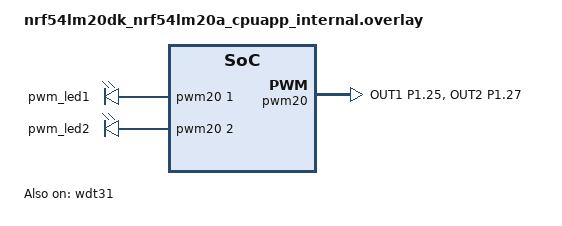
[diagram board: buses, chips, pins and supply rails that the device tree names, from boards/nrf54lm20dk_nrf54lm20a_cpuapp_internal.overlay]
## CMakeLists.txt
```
#
# Copyright (c) 2022 Nordic Semiconductor ASA
#
# SPDX-License-Identifier: LicenseRef-Nordic-5-Clause
#

cmake_minimum_required(VERSION 3.20.0)

find_package(Zephyr HINTS $ENV{ZEPHYR_BASE})

project(matter-window-app)

# Enable GNU STD support.
include(${ZEPHYR_CONNECTEDHOMEIP_MODULE_DIR}/config/nrfconnect/app/enable-gnu-std.cmake)

# NORDIC SDK APP START

# Include all source files that are located in the Matter common directory.
include(${ZEPHYR_NRF_MODULE_DIR}/samples/matter/common/cmake/source_common.cmake)

# Include Data Model utils
include(${ZEPHYR_NRF_MODULE_DIR}/samples/matter/common/cmake/data_model.cmake)

target_include_directories(app PRIVATE
    src
    ${CONFIG_NCS_MATTER_ZAP_FILES_PATH}
)

target_sources(app PRIVATE
    src/app_task.cpp
    src/window_covering.cpp
    src/main.cpp
    src/zcl_callbacks.cpp
)

ncs_configure_data_model(
    ZAP_FILE ${CMAKE_CURRENT_SOURCE_DIR}/${CONFIG_NCS_MATTER_ZAP_FILES_PATH}/window-app.zap
)
# NORDIC SDK APP END
```

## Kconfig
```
#
# Copyright (c) 2022 Nordic Semiconductor ASA
#
# SPDX-License-Identifier: LicenseRef-Nordic-5-Clause
#

mainmenu "Matter nRF Connect Window Covering Example Application"

config STATE_LEDS
	bool "Use LEDs to indicate the device state"
	default y
	help
	  Use LEDs to render the current state of the device such as the progress of commissioning of
	  the device into a network or the factory reset initiation. Note that setting this option to
	  'n' does not disable the LED indicating the state of the simulated bolt.

if MPSL_FEM

config OPENTHREAD_DEFAULT_TX_POWER
	int "Set the default 802.15.4 output power (dBm) for device with FEM"
	range -40 20
	default 20
	help
	  Use this setting to set the default Thread (802.15.4) output power for device that
	  uses FEM. This value has a unit in dBm and represents the Tx power at Antenna port of FEM device.

# override FEM GAIN to 20 dB as a default
# see subsys/mpsl/fem/Kconfig
# Leave MPSL_FEM_NRF21540_TX_GAIN_DB unchanged when OPENTHREAD_DEFAULT_TX_POWER=0 
# to set the output power to a similar value as for nRF52840DK.
config MPSL_FEM_NRF21540_TX_GAIN_DB
	default 20 if OPENTHREAD_DEFAULT_TX_POWER != 0

endif # MPSL_FEM


source "${ZEPHYR_BASE}/../modules/lib/matter/config/nrfconnect/chip-module/Kconfig.features"
source "${ZEPHYR_BASE}/../modules/lib/matter/config/nrfconnect/chip-module/Kconfig.defaults"
source "Kconfig.zephyr"
```

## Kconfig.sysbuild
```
#
# Copyright (c) 2023 Nordic Semiconductor ASA
#
# SPDX-License-Identifier: LicenseRef-Nordic-5-Clause
#

config PARTITION_MANAGER
	default n if SOC_SERIES_NRF52X || SOC_NRF54L15 || SOC_NRF54LM20A

#### Radio core selection
config NRF_DEFAULT_IPC_RADIO
	default y

# Enable IEEE802.15.4 serialization to network core
# This config automatically pulls in the `overlay-802154.conf` in the ipc_radio image
config NETCORE_IPC_RADIO_IEEE802154
	default y if SOC_SERIES_NRF53X

# Enable Bluetooth serialization to network core
# This config automatically pulls in the `overlay-bt_hci_ipc.conf` in the ipc_radio image
config NETCORE_IPC_RADIO_BT_HCI_IPC
	default y if SOC_SERIES_NRF53X

#### Bootloader
choice BOOTLOADER
	default BOOTLOADER_MCUBOOT if !BOARD_NRF21540DK
endchoice

if BOOTLOADER_MCUBOOT

#### DFU multi-image support
config DFU_MULTI_IMAGE_PACKAGE_BUILD
	default y

config DFU_MULTI_IMAGE_PACKAGE_APP
	default y

config PM_EXTERNAL_FLASH_MCUBOOT_SECONDARY
	default y

#### DFU network core configuration
if SOC_SERIES_NRF53X

choice MCUBOOT_MODE
	default MCUBOOT_MODE_OVERWRITE_ONLY
endchoice

choice BOOT_SIGNATURE_TYPE
	default BOOT_SIGNATURE_TYPE_RSA
endchoice

config SECURE_BOOT_NETCORE
	default y

config NETCORE_APP_UPDATE
	default y

config DFU_MULTI_IMAGE_PACKAGE_NET
	default y

endif # SOC_SERIES_NRF53X

if BOARD_NRF54L15DK || BOARD_NRF54LM20DK

# Disable checking the external drivers for nRF54L15 and nRF54LM20 DKs.
config PM_OVERRIDE_EXTERNAL_DRIVER_CHECK
	default y

endif # BOARD_NRF54L15DK || BOARD_NRF54LM20DK

endif # BOOTLOADER_MCUBOOT

#### Enable generating factory data
config MATTER_FACTORY_DATA_GENERATE
	default y if !BOARD_NRF21540DK

source "share/sysbuild/Kconfig"
```

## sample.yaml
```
sample:
  description: Matter Window Covering example
  name: Matter Window Covering
tests:
  sample.matter.window_cover.debug:
    sysbuild: true
    build_only: true
    integration_platforms:
      - nrf52840dk/nrf52840
      - nrf5340dk/nrf5340/cpuapp
    platform_allow: nrf52840dk/nrf52840 nrf5340dk/nrf5340/cpuapp
    tags: sysbuild
  sample.matter.window_cover.release:
    sysbuild: true
    build_only: true
    extra_args: FILE_SUFFIX=release
      SB_CONFIG_BOOTLOADER_MCUBOOT=y SB_CONFIG_PARTITION_MANAGER=y
    integration_platforms:
      - nrf52840dk/nrf52840
      - nrf5340dk/nrf5340/cpuapp
      - nrf54l15pdk/nrf54l15/cpuapp
      - nrf54l15pdk@0.3.0/nrf54l15/cpuapp
    platform_allow: nrf52840dk/nrf52840 nrf5340dk/nrf5340/cpuapp
      nrf54l15pdk/nrf54l15/cpuapp nrf54l15pdk@0.3.0/nrf54l15/cpuapp
    tags: sysbuild
```

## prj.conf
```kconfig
#
# Copyright (c) 2022 Nordic Semiconductor ASA
#
# SPDX-License-Identifier: LicenseRef-Nordic-5-Clause
#

# This sample uses Kconfig.defaults to set options common for all
# samples. This file should contain only options specific for this sample
# or overrides of default values.

# Enable CHIP
CONFIG_CHIP=y
CONFIG_CHIP_PROJECT_CONFIG="src/chip_project_config.h"
# 32784 == 0x8010 (example window-app)
CONFIG_CHIP_DEVICE_PRODUCT_ID=32784
CONFIG_STD_CPP17=y

# Enable Matter pairing automatically on application start.
CONFIG_CHIP_ENABLE_PAIRING_AUTOSTART=y

# Enable Matter extended announcement and increase duration to 1 hour.
CONFIG_CHIP_BLE_EXT_ADVERTISING=y
CONFIG_CHIP_BLE_ADVERTISING_DURATION=60

# Add support for LEDs and buttons on Nordic development kits
CONFIG_DK_LIBRARY=y

# PWM support
CONFIG_PWM=y

# OpenThread configs
CONFIG_OPENTHREAD_NORDIC_LIBRARY_MTD=y
CONFIG_OPENTHREAD_MTD=y
CONFIG_OPENTHREAD_FTD=n
CONFIG_CHIP_ENABLE_ICD_SUPPORT=y
CONFIG_CHIP_THREAD_SSED=y
CONFIG_CHIP_ICD_SLOW_POLL_INTERVAL=500
CONFIG_CHIP_ICD_FAST_POLLING_INTERVAL=500

# Bluetooth Low Energy configuration
CONFIG_BT_DEVICE_NAME="MatterWinCov"

# Suspend devices when the CPU goes into sleep
CONFIG_PM_DEVICE=y

# Stack size settings
CONFIG_IEEE802154_NRF5_RX_STACK_SIZE=1024

# Other settings
CONFIG_THREAD_NAME=y
CONFIG_MPU_STACK_GUARD=y
CONFIG_RESET_ON_FATAL_ERROR=n
CONFIG_CHIP_LIB_SHELL=y
CONFIG_NCS_MATTER_TEST_SHELL=y

# Reduce application size
CONFIG_USE_SEGGER_RTT=n

# Enable Factory Data feature
CONFIG_CHIP_FACTORY_DATA=y
CONFIG_CHIP_FACTORY_DATA_BUILD=y
```

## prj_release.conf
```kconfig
#
# Copyright (c) 2022 Nordic Semiconductor ASA
#
# SPDX-License-Identifier: LicenseRef-Nordic-5-Clause
#

# This sample uses Kconfig.defaults to set options common for all
# samples. This file should contain only options specific for this sample
# or overrides of default values.

# Enable CHIP
CONFIG_CHIP=y
CONFIG_CHIP_PROJECT_CONFIG="src/chip_project_config.h"
# 32784 == 0x8010 (example window-app)
CONFIG_CHIP_DEVICE_PRODUCT_ID=32784
CONFIG_STD_CPP17=y

# Enable Matter pairing automatically on application start.
CONFIG_CHIP_ENABLE_PAIRING_AUTOSTART=y

# Enable Matter extended announcement and increase duration to 1 hour.
CONFIG_CHIP_BLE_EXT_ADVERTISING=y
CONFIG_CHIP_BLE_ADVERTISING_DURATION=60

# Add support for LEDs and buttons on Nordic development kits
CONFIG_DK_LIBRARY=y

# Try to disable unused RAM blocks to reduce power consumption
CONFIG_RAM_POWER_DOWN_LIBRARY=y

# PWM support
CONFIG_PWM=y

# OpenThread configs
CONFIG_OPENTHREAD_NORDIC_LIBRARY_MTD=y
CONFIG_OPENTHREAD_MTD=y
CONFIG_OPENTHREAD_FTD=n
CONFIG_CHIP_ENABLE_ICD_SUPPORT=y
CONFIG_CHIP_THREAD_SSED=y
CONFIG_CHIP_ICD_SLOW_POLL_INTERVAL=500
CONFIG_CHIP_ICD_FAST_POLLING_INTERVAL=500

# Bluetooth Low Energy configuration
CONFIG_BT_DEVICE_NAME="MatterWinCov"

# Suspend devices when the CPU goes into sleep
CONFIG_PM_DEVICE=y

# Stack size settings
CONFIG_IEEE802154_NRF5_RX_STACK_SIZE=1024

# Enable system reset on fatal error
CONFIG_RESET_ON_FATAL_ERROR=y

# Disable all debug features
CONFIG_USE_SEGGER_RTT=n
CONFIG_SHELL=n
CONFIG_OPENTHREAD_SHELL=n
CONFIG_CONSOLE=n
CONFIG_UART_CONSOLE=n
CONFIG_SERIAL=n
CONFIG_LOG=n
CONFIG_LOG_MODE_MINIMAL=n
CONFIG_ASSERT_VERBOSE=n
CONFIG_ASSERT_NO_FILE_INFO=y
CONFIG_PRINTK=n
CONFIG_PRINTK_SYNC=n
CONFIG_THREAD_NAME=n
CONFIG_BOOT_BANNER=n

# Enable Factory Data feature
CONFIG_CHIP_FACTORY_DATA=y
CONFIG_CHIP_FACTORY_DATA_BUILD=y

# Enable Watchdog
CONFIG_NCS_MATTER_WATCHDOG=y

# Enable LTO to decrease the flash usage.
CONFIG_LTO=y
CONFIG_ISR_TABLES_LOCAL_DECLARATION=y
```

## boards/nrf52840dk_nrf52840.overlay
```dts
/*
 * Copyright (c) 2021 Nordic Semiconductor ASA
 *
 * SPDX-License-Identifier: LicenseRef-Nordic-5-Clause
 */

#include "../../common/boards/nrf52840dk_nrf52840_partitions.dtsi"

/ {
	/*
	* Configure LED2 and LED3 to show the state of the
	* window cover,by using the LED's brightness level.
	*/
	aliases {
		pwm-led1 = &pwm_led1;
		pwm-led2 = &pwm_led2;
	};

	pwmleds {
		pwm_led1: pwm_led_1 {
			pwms = <&pwm0 1 PWM_MSEC(20) PWM_POLARITY_INVERTED>;
		};
		pwm_led2: pwm_led_2 {
			pwms = <&pwm0 2 PWM_MSEC(20) PWM_POLARITY_INVERTED>;
		};
	};
};

&pwm0 {
	pinctrl-0 = <&pwm0_default_alt>;
	pinctrl-1 = <&pwm0_sleep_alt>;
	pinctrl-names = "default", "sleep";
};

&pinctrl {
	pwm0_default_alt: pwm0_default_alt {
		group1 {
			psels = <NRF_PSEL(PWM_OUT1, 0, 14)>, <NRF_PSEL(PWM_OUT2, 0, 15)>;
			nordic,invert;
		};
	};

	pwm0_sleep_alt: pwm0_sleep_alt {
		group1 {
			psels = <NRF_PSEL(PWM_OUT1, 0, 14)>, <NRF_PSEL(PWM_OUT2, 0, 15)>;
			low-power-enable;
		};
	};
};

/* Disable unused peripherals to reduce power consumption */
&adc {
	status = "disabled";
};

&uart1 {
	status = "disabled";
};

&i2c0 {
	status = "disabled";
};

&spi1 {
	status = "disabled";
};

&spi3 {
	status = "disabled";
};

&usbd {
	status = "disabled";
};
```

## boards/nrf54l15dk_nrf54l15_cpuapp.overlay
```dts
/*
 * Copyright (c) 2024 Nordic Semiconductor ASA
 *
 * SPDX-License-Identifier: LicenseRef-Nordic-5-Clause
 */

#include "../../common/boards/nrf54l15dk_nrf54l15_cpuapp_partitions.dtsi"

/ {
	aliases {
		/* Configure PWM module for led1 (LED2 on the board) */
		pwm-led1 = &pwm_led1;
		pwm-led2 = &pwm_led2;

		/* Use watchdog wdt31 as the application watchdog */
		watchdog0 = &wdt31;
	};

	pwmleds {
		compatible = "pwm-leds";
		pwm_led1: pwm_led_1 {
			pwms = <&pwm20 1 PWM_MSEC(20) PWM_POLARITY_NORMAL>;
		};
		pwm_led2: pwm_led_2 {
			pwms = <&pwm20 2 PWM_MSEC(20) PWM_POLARITY_NORMAL>;
		};
	};
};

/* TODO: re-enable HWFC once it's fixed */
&uart20 {
	/delete-property/ hw-flow-control;
};

&pwm20 {
	status = "okay";
	pinctrl-0 = <&pwm_default>;
	pinctrl-1 = <&pwm_sleep>;
	pinctrl-names = "default", "sleep";
};

&pinctrl {
	pwm_default: pwm_default {
		group1 {
			psels = <NRF_PSEL(PWM_OUT1, 1, 10)>, <NRF_PSEL(PWM_OUT2, 1, 14)>;
		};
	};
	pwm_sleep: pwm_sleep {
		group1 {
			psels = <NRF_PSEL(PWM_OUT1, 1, 10)>, <NRF_PSEL(PWM_OUT2, 1, 14)>;
			low-power-enable;
		};
	};
};

&wdt31 {
	status = "okay";
};
```

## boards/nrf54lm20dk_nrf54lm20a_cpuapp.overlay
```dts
/*
 * Copyright (c) 2025 Nordic Semiconductor ASA
 *
 * SPDX-License-Identifier: LicenseRef-Nordic-5-Clause
 */

#include <samples/matter/nrf54lm20a_partitions.dtsi>

/ {
	aliases {
		/* Use watchdog wdt31 as the application watchdog */
		watchdog0 = &wdt31;
	};
};

&wdt31 {
	status = "okay";
};
```

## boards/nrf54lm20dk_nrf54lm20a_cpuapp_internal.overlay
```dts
/*
 * Copyright (c) 2025 Nordic Semiconductor ASA
 *
 * SPDX-License-Identifier: LicenseRef-Nordic-5-Clause
 */

#include "../../common/boards/nrf54lm20dk_nrf54lm20a_cpuapp_internal_partitions.dtsi"

/ {
	aliases {
		/* Configure PWM module for led1 (LED2 on the board) */
		pwm-led1 = &pwm_led1;

		/* Use watchdog wdt31 as the application watchdog */
		watchdog0 = &wdt31;
	};

	pwmleds {
		compatible = "pwm-leds";

		pwm_led1: pwm_led_1 {
			pwms = <&pwm20 1 PWM_MSEC(20) PWM_POLARITY_NORMAL>;
		};

		pwm_led2: pwm_led_2 {
			pwms = <&pwm20 2 PWM_MSEC(20) PWM_POLARITY_NORMAL>;
		};
	};
};

&pwm20 {
	status = "okay";
	pinctrl-0 = <&pwm_default>;
	pinctrl-1 = <&pwm_sleep>;
	pinctrl-names = "default", "sleep";
};

&pinctrl {
	pwm_default: pwm_default {
		group1 {
			psels = <NRF_PSEL(PWM_OUT1, 1, 25)>, <NRF_PSEL(PWM_OUT2, 1, 27)>;
		};
	};

	pwm_sleep: pwm_sleep {
		group1 {
			psels = <NRF_PSEL(PWM_OUT1, 1, 25)>, <NRF_PSEL(PWM_OUT2, 1, 27)>;
			low-power-enable;
		};
	};
};

&wdt31 {
	status = "okay";
};
```

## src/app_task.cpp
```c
/*
 * Copyright (c) 2022 Nordic Semiconductor ASA
 *
 * SPDX-License-Identifier: LicenseRef-Nordic-5-Clause
 */

#include "app_task.h"

#include "app_config.h"
#include "led_util.h"
#include "window_covering.h"

#include <app-common/zap-generated/attribute-id.h>
#include <app-common/zap-generated/attribute-type.h>
#include <app-common/zap-generated/cluster-id.h>
#include <app/clusters/identify-server/identify-server.h>
#include <app/server/OnboardingCodesUtil.h>
#include <app/server/Server.h>
#include <app/util/attribute-storage.h>
#include <credentials/DeviceAttestationCredsProvider.h>
#include <credentials/examples/DeviceAttestationCredsExample.h>

#ifdef CONFIG_CHIP_OTA_REQUESTOR
#include "ota_util.h"
#endif

#include <dk_buttons_and_leds.h>
#include <zephyr/logging/log.h>
#include <zephyr/kernel.h>

LOG_MODULE_DECLARE(app, CONFIG_MATTER_LOG_LEVEL);

using namespace ::chip;
using namespace ::chip::app;
using namespace ::chip::Credentials;
using namespace ::chip::DeviceLayer;

namespace
{
constexpr uint32_t kFactoryResetTriggerTimeout = 3000;
constexpr uint32_t kFactoryResetCancelWindowTimeout = 3000;
constexpr size_t kAppEventQueueSize = 10;

K_MSGQ_DEFINE(sAppEventQueue, sizeof(AppEvent), kAppEventQueueSize, alignof(AppEvent));
k_timer sFunctionTimer;

Identify sIdentify = { WindowCovering::Endpoint(), AppTask::IdentifyStartHandler, AppTask::IdentifyStopHandler,
		       EMBER_ZCL_IDENTIFY_IDENTIFY_TYPE_VISIBLE_LED };

LEDWidget sStatusLED;
LEDWidget sIdentifyLED;
FactoryResetLEDsWrapper<1> sFactoryResetLEDs{ { FACTORY_RESET_SIGNAL_LED } };

bool sIsNetworkProvisioned = false;
bool sIsNetworkEnabled = false;
bool sHaveBLEConnections = false;
} /* namespace */

namespace LedConsts
{
constexpr uint32_t kBlinkRate_ms{ 500 };
constexpr uint32_t kIdentifyBlinkRate_ms{ 500 };

namespace StatusLed
{
	namespace Unprovisioned
	{
		constexpr uint32_t kOn_ms{ 100 };
		constexpr uint32_t kOff_ms{ kOn_ms };
	} /* namespace Unprovisioned */
	namespace Provisioned
	{
		constexpr uint32_t kOn_ms{ 50 };
		constexpr uint32_t kOff_ms{ 950 };
	} /* namespace Provisioned */

} /* namespace StatusLed */
} /* namespace LedConsts */

CHIP_ERROR AppTask::Init()
{
	/* Initialize CHIP stack */
	LOG_INF("Init CHIP stack");

	CHIP_ERROR err = chip::Platform::MemoryInit();
	if (err != CHIP_NO_ERROR) {
		LOG_ERR("Platform::MemoryInit() failed");
		return err;
	}

	err = PlatformMgr().InitChipStack();
	if (err != CHIP_NO_ERROR) {
		LOG_ERR("PlatformMgr().InitChipStack() failed");
		return err;
	}

	err = ThreadStackMgr().InitThreadStack();
	if (err != CHIP_NO_ERROR) {
		LOG_ERR("ThreadStackMgr().InitThreadStack() failed: %s", ErrorStr(err));
		return err;
	}

#if CONFIG_CHIP_THREAD_SSED
	err = ConnectivityMgr().SetThreadDeviceType(ConnectivityManager::kThreadDeviceType_SynchronizedSleepyEndDevice);
#elif CONFIG_OPENTHREAD_MTD_SED
	err = ConnectivityMgr().SetThreadDeviceType(ConnectivityManager::kThreadDeviceType_SleepyEndDevice);
#else
	err = ConnectivityMgr().SetThreadDeviceType(ConnectivityManager::kThreadDeviceType_MinimalEndDevice);
#endif
	if (err != CHIP_NO_ERROR) {
		LOG_ERR("ConnectivityMgr().SetThreadDeviceType() failed: %s", ErrorStr(err));
		return err;
	}

	/* Initialize LEDs */
	LEDWidget::InitGpio();
	LEDWidget::SetStateUpdateCallback(LEDStateUpdateHandler);

	sStatusLED.Init(SYSTEM_STATE_LED);
	sIdentifyLED.Init(LIFT_STATE_LED);
	sIdentifyLED.Set(false);

	UpdateStatusLED();

	/* Initialize buttons */
	int ret = dk_buttons_init(ButtonEventHandler);
	if (ret) {
		LOG_ERR("dk_buttons_init() failed");
		return chip::System::MapErrorZephyr(ret);
	}

	/* Initialize function timer */
	k_timer_init(&sFunctionTimer, &AppTask::FunctionTimerTimeoutCallback, nullptr);
	k_timer_user_data_set(&sFunctionTimer, this);

#ifdef CONFIG_MCUMGR_SMP_BT
	/* Initialize DFU over SMP */
	GetDFUOverSMP().Init(RequestSMPAdvertisingStart);
	GetDFUOverSMP().ConfirmNewImage();
#endif

	/* Initialize CHIP server */
#if CONFIG_CHIP_FACTORY_DATA
	ReturnErrorOnFailure(mFactoryDataProvider.Init());
	SetDeviceInstanceInfoProvider(&mFactoryDataProvider);
	SetDeviceAttestationCredentialsProvider(&mFactoryDataProvider);
	SetCommissionableDataProvider(&mFactoryDataProvider);
#else
	SetDeviceAttestationCredentialsProvider(Examples::GetExampleDACProvider());
#endif

	static CommonCaseDeviceServerInitParams initParams;
	(void)initParams.InitializeStaticResourcesBeforeServerInit();

	ReturnErrorOnFailure(chip::Server::GetInstance().Init(initParams));
	ConfigurationMgr().LogDeviceConfig();
	PrintOnboardingCodes(chip::RendezvousInformationFlags(chip::RendezvousInformationFlag::kBLE));

	/*
	 * Add CHIP event handler and start CHIP thread.
	 * Note that all the initialization code should happen prior to this point to avoid data races
	 * between the main and the CHIP threads.
	 */
	PlatformMgr().AddEventHandler(ChipEventHandler, 0);

	err = PlatformMgr().StartEventLoopTask();
	if (err != CHIP_NO_ERROR) {
		LOG_ERR("PlatformMgr().StartEventLoopTask() failed");
		return err;
	}

	WindowCovering::Instance().PositionLEDUpdate(WindowCovering::MoveType::LIFT);
	WindowCovering::Instance().PositionLEDUpdate(WindowCovering::MoveType::TILT);

	return CHIP_NO_ERROR;
}

CHIP_ERROR AppTask::StartApp()
{
	ReturnErrorOnFailure(Init());

	AppEvent event = {};

	while (true) {
		k_msgq_get(&sAppEventQueue, &event, K_FOREVER);
		DispatchEvent(event);
	}

	return CHIP_NO_ERROR;
}

void AppTask::IdentifyStartHandler(Identify *)
{
	AppEvent event;
	event.Type = AppEventType::IdentifyStart;
	event.Handler = [](const AppEvent &) {
		WindowCovering::Instance().GetLiftIndicator().SuppressOutput();
		sIdentifyLED.Blink(LedConsts::kIdentifyBlinkRate_ms);
	};
	PostEvent(event);
}

void AppTask::IdentifyStopHandler(Identify *)
{
	AppEvent event;
	event.Type = AppEventType::IdentifyStop;
	event.Handler = [](const AppEvent &) {
		sIdentifyLED.Set(false);
		WindowCovering::Instance().GetLiftIndicator().ApplyLevel();
	};
	PostEvent(event);
}

void AppTask::ButtonEventHandler(uint32_t buttonState, uint32_t hasChanged)
{
	AppEvent event;
	event.Type = AppEventType::Button;

	if (FUNCTION_BUTTON_MASK & hasChanged) {
		event.ButtonEvent.PinNo = FUNCTION_BUTTON;
		event.ButtonEvent.Action =
			static_cast<uint8_t>((FUNCTION_BUTTON_MASK & buttonState) ? AppEventType::ButtonPushed :
										    AppEventType::ButtonReleased);
		event.Handler = FunctionHandler;
		PostEvent(event);
	}

	if (BLE_ADVERTISEMENT_START_BUTTON_MASK & buttonState & hasChanged) {
		event.ButtonEvent.PinNo = BLE_ADVERTISEMENT_START_BUTTON;
		event.ButtonEvent.Action = static_cast<uint8_t>(AppEventType::ButtonPushed);
		event.Handler = StartBLEAdvertisementHandler;
		PostEvent(event);
	}

	if (OPEN_BUTTON_MASK & hasChanged) {
		event.ButtonEvent.PinNo = OPEN_BUTTON;
		event.ButtonEvent.Action = static_cast<uint8_t>(
			(OPEN_BUTTON_MASK & buttonState) ? AppEventType::ButtonPushed : AppEventType::ButtonReleased);
		event.Handler = OpenHandler;
		PostEvent(event);
	}

	if (CLOSE_BUTTON_MASK & hasChanged) {
		event.ButtonEvent.PinNo = CLOSE_BUTTON;
		event.ButtonEvent.Action = static_cast<uint8_t>(
			(CLOSE_BUTTON_MASK & buttonState) ? AppEventType::ButtonPushed : AppEventType::ButtonReleased);
		event.Handler = CloseHandler;
		PostEvent(event);
	}
}

#ifdef CONFIG_MCUMGR_SMP_BT
void AppTask::RequestSMPAdvertisingStart(void)
{
	AppEvent event;
	event.Type = AppEventType::StartSMPAdvertising;
	event.Handler = [](const AppEvent &) { GetDFUOverSMP().StartBLEAdvertising(); };
	PostEvent(event);
}
#endif

void AppTask::FunctionTimerTimeoutCallback(k_timer *timer)
{
	if (!timer) {
		return;
	}

	AppEvent event;
	event.Type = AppEventType::Timer;
	event.TimerEvent.Context = k_timer_user_data_get(timer);
	event.Handler = FunctionTimerEventHandler;
	PostEvent(event);
}

void AppTask::FunctionTimerEventHandler(const AppEvent &event)
{
	if (event.Type != AppEventType::Timer)
		return;

	/* If we reached here, the button was held past kFactoryResetTriggerTimeout, initiate factory reset */
	if (Instance().mFunctionTimerActive && Instance().mFunction == FunctionEvent::SoftwareUpdate) {
		LOG_INF("Factory Reset Triggered. Release button within %ums to cancel.", kFactoryResetTriggerTimeout);

		/* Start timer for kFactoryResetCancelWindowTimeout to allow user to cancel, if required. */
		Instance().StartTimer(kFactoryResetCancelWindowTimeout);
		Instance().mFunction = FunctionEvent::FactoryReset;

#ifdef CONFIG_STATE_LEDS
		/* Turn off all LEDs before starting blink to make sure blink is co-ordinated. */
		sStatusLED.Set(false);
		sFactoryResetLEDs.Set(false);

		sStatusLED.Blink(LedConsts::kBlinkRate_ms);
		sFactoryResetLEDs.Blink(LedConsts::kBlinkRate_ms);
#endif
	} else if (Instance().mFunctionTimerActive && Instance().mFunction == FunctionEvent::FactoryReset) {
		/* Actually trigger Factory Reset */
		Instance().mFunction = FunctionEvent::NoneSelected;

		chip::Server::GetInstance().ScheduleFactoryReset();
	}
}

void AppTask::FunctionHandler(const AppEvent &event)
{
	if (event.ButtonEvent.PinNo != FUNCTION_BUTTON)
		return;

	/* To initiate factory reset: press the FUNCTION_BUTTON for kFactoryResetTriggerTimeout + */
	/* kFactoryResetCancelWindowTimeout. LED1 AND LED4 start blinking after kFactoryResetTriggerTimeout to
	 * signal */
	/* factory reset has been initiated. To cancel factory reset: release the FUNCTION_BUTTON once all LEDs start */
	/* blinking within the kFactoryResetCancelWindowTimeout */
	if (event.ButtonEvent.Action == static_cast<uint8_t>(AppEventType::ButtonPushed)) {
		if (!Instance().mFunctionTimerActive && Instance().mFunction == FunctionEvent::NoneSelected) {
			Instance().StartTimer(kFactoryResetTriggerTimeout);

			Instance().mFunction = FunctionEvent::SoftwareUpdate;
		}
	} else {
		/* If the button was released before factory reset got initiated, trigger a software update. */
		if (Instance().mFunctionTimerActive && Instance().mFunction == FunctionEvent::SoftwareUpdate) {
			Instance().CancelTimer();

#ifdef CONFIG_MCUMGR_SMP_BT
			GetDFUOverSMP().StartServer();
#else
			LOG_INF("Software update is disabled");
#endif
			Instance().mFunction = FunctionEvent::NoneSelected;
		} else if (Instance().mFunctionTimerActive && Instance().mFunction == FunctionEvent::FactoryReset) {
			sFactoryResetLEDs.Set(false);

			UpdateStatusLED();
			Instance().CancelTimer();
			Instance().mFunction = FunctionEvent::NoneSelected;
			LOG_INF("Factory Reset has been Canceled");
		} else if (Instance().mFunctionTimerActive) {
			CancelTimer();
			Instance().mFunction = FunctionEvent::NoneSelected;
		}
	}
}

void AppTask::StartBLEAdvertisementHandler(const AppEvent &)
{
	if (Server::GetInstance().GetFabricTable().FabricCount() != 0) {
		LOG_INF("Matter service BLE advertising not started - device is already commissioned");
		return;
	}

	if (ConnectivityMgr().IsBLEAdvertisingEnabled()) {
		LOG_INF("BLE advertising is already enabled");
		return;
	}

	if (Server::GetInstance().GetCommissioningWindowManager().OpenBasicCommissioningWindow() != CHIP_NO_ERROR) {
		LOG_ERR("OpenBasicCommissioningWindow() failed");
	}
}

void AppTask::OpenHandler(const AppEvent &event)
{
	if (event.ButtonEvent.PinNo != OPEN_BUTTON || Instance().mFunction != FunctionEvent::NoneSelected)
		return;

	if (event.ButtonEvent.Action == static_cast<uint8_t>(AppEventType::ButtonPushed)) {
		Instance().mOpenButtonIsPressed = true;
		if (Instance().mCloseButtonIsPressed) {
			Instance().ToggleMoveType();
		}
	} else if (event.ButtonEvent.Action == static_cast<uint8_t>(AppEventType::ButtonReleased)) {
		if (!Instance().mCloseButtonIsPressed) {
			if (!Instance().mMoveTypeRecentlyChanged) {
				WindowCovering::Instance().SetSingleStepTarget(OperationalState::MovingUpOrOpen);
			} else {
				Instance().mMoveTypeRecentlyChanged = false;
			}
		}
		Instance().mOpenButtonIsPressed = false;
	}
}

void AppTask::CloseHandler(const AppEvent &event)
{
	if (event.ButtonEvent.PinNo != CLOSE_BUTTON || Instance().mFunction != FunctionEvent::NoneSelected)
		return;

	if (event.ButtonEvent.Action == static_cast<uint8_t>(AppEventType::ButtonPushed)) {
		Instance().mCloseButtonIsPressed = true;
		if (Instance().mOpenButtonIsPressed) {
			Instance().ToggleMoveType();
		}
	} else if (event.ButtonEvent.Action == static_cast<uint8_t>(AppEventType::ButtonReleased)) {
		if (!Instance().mOpenButtonIsPressed) {
			if (!Instance().mMoveTypeRecentlyChanged) {
				WindowCovering::Instance().SetSingleStepTarget(OperationalState::MovingDownOrClose);
			} else {
				Instance().mMoveTypeRecentlyChanged = false;
			}
		}
		Instance().mCloseButtonIsPressed = false;
	}
}

void AppTask::ToggleMoveType()
{
	if (WindowCovering::Instance().GetMoveType() == WindowCovering::MoveType::LIFT) {
		WindowCovering::Instance().SetMoveType(WindowCovering::MoveType::TILT);
		LOG_INF("Window covering move: tilt");
	} else {
		WindowCovering::Instance().SetMoveType(WindowCovering::MoveType::LIFT);
		LOG_INF("Window covering move: lift");
	}
	mMoveTypeRecentlyChanged = true;
}

void AppTask::UpdateLedStateEventHandler(const AppEvent &event)
{
	if (event.Type == AppEventType::UpdateLedState) {
		event.UpdateLedStateEvent.LedWidget->UpdateState();
	}
}

void AppTask::LEDStateUpdateHandler(LEDWidget &ledWidget)
{
	AppEvent event;
	event.Type = AppEventType::UpdateLedState;
	event.Handler = UpdateLedStateEventHandler;
	event.UpdateLedStateEvent.LedWidget = &ledWidget;
	PostEvent(event);
}

void AppTask::UpdateStatusLED()
{
	/* Update the status LED.
	 *
	 * If IPv6 network and service provisioned, keep the LED On constantly.
	 *
	 * If the system has ble connection(s) uptill the stage above, THEN blink the LED at an even
	 * rate of 100ms.
	 *
	 * Otherwise, blink the LED for a very short time. */
	if (sIsNetworkProvisioned && sIsNetworkEnabled) {
		sStatusLED.Set(true);
	} else if (sHaveBLEConnections) {
		sStatusLED.Blink(LedConsts::StatusLed::Unprovisioned::kOn_ms,
				 LedConsts::StatusLed::Unprovisioned::kOff_ms);
	} else {
		sStatusLED.Blink(LedConsts::StatusLed::Provisioned::kOn_ms, LedConsts::StatusLed::Provisioned::kOff_ms);
	}
}

void AppTask::ChipEventHandler(const ChipDeviceEvent *event, intptr_t /* arg */)
{
	switch (event->Type) {
	case DeviceEventType::kCHIPoBLEAdvertisingChange:
#ifdef CONFIG_CHIP_NFC_COMMISSIONING
		if (event->CHIPoBLEAdvertisingChange.Result == kActivity_Started) {
			if (NFCMgr().IsTagEmulationStarted()) {
				LOG_INF("NFC Tag emulation is already started");
			} else {
				ShareQRCodeOverNFC(
					chip::RendezvousInformationFlags(chip::RendezvousInformationFlag::kBLE));
			}
		} else if (event->CHIPoBLEAdvertisingChange.Result == kActivity_Stopped) {
			NFCMgr().StopTagEmulation();
		}
#endif
		sHaveBLEConnections = ConnectivityMgr().NumBLEConnections() != 0;
		UpdateStatusLED();
		break;
	case DeviceEventType::kThreadStateChange:
		sIsNetworkProvisioned = ConnectivityMgr().IsThreadProvisioned();
		sIsNetworkEnabled = ConnectivityMgr().IsThreadEnabled();
		UpdateStatusLED();
		break;
	case DeviceEventType::kDnssdPlatformInitialized:
#if CONFIG_CHIP_OTA_REQUESTOR
		InitBasicOTARequestor();
#endif
		break;
	default:
		break;
	}
}

void AppTask::CancelTimer()
{
	k_timer_stop(&sFunctionTimer);
	Instance().mFunctionTimerActive = false;
}

void AppTask::StartTimer(uint32_t timeoutMs)
{
	k_timer_start(&sFunctionTimer, K_MSEC(timeoutMs), K_NO_WAIT);
	Instance().mFunctionTimerActive = true;
}

void AppTask::PostEvent(const AppEvent &event)
{
	if (k_msgq_put(&sAppEventQueue, &event, K_NO_WAIT)) {
		LOG_INF("Failed to post event to app task event queue");
	}
}

void AppTask::DispatchEvent(const AppEvent &event)
{
	if (event.Handler) {
		event.Handler(event);
	} else {
		LOG_INF("Event received with no handler. Dropping event.");
	}
}
```
